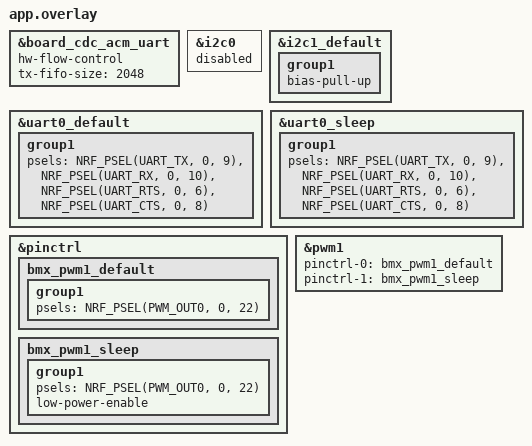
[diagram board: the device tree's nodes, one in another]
/* Preserve console writes when USB CDC transmission briefly outpaces the host. */
&board_cdc_acm_uart {
    hw-flow-control;
    tx-fifo-size = <2048>;
};

/* I2C0 shares hardware instance 0 with UART0. Use independent I2C1. */
&i2c0 {
    status = "disabled";
};

&i2c1_default {
    group1 {
        bias-pull-up;
    };
};

/* UART0 uses D10/D16 for data and D3/D2 for the RTS/CTS handshake. */
&uart0_default {
    group1 {
        psels = <NRF_PSEL(UART_TX, 0, 9)>,
                <NRF_PSEL(UART_RX, 0, 10)>,
                <NRF_PSEL(UART_RTS, 0, 6)>,
                <NRF_PSEL(UART_CTS, 0, 8)>;
    };
};

&uart0_sleep {
    group1 {
        psels = <NRF_PSEL(UART_TX, 0, 9)>,
                <NRF_PSEL(UART_RX, 0, 10)>,
                <NRF_PSEL(UART_RTS, 0, 6)>,
                <NRF_PSEL(UART_CTS, 0, 8)>;
    };
};

/* An independent PWM output on the exposed D4 / P0.22 pad. */
&pinctrl {
    bmx_pwm1_default: bmx_pwm1_default {
        group1 {
            psels = <NRF_PSEL(PWM_OUT0, 0, 22)>;
        };
    };

    bmx_pwm1_sleep: bmx_pwm1_sleep {
        group1 {
            psels = <NRF_PSEL(PWM_OUT0, 0, 22)>;
            low-power-enable;
        };
    };
};

&pwm1 {
    status = "okay";
    pinctrl-0 = <&bmx_pwm1_default>;
    pinctrl-1 = <&bmx_pwm1_sleep>;
    pinctrl-names = "default", "sleep";
};
